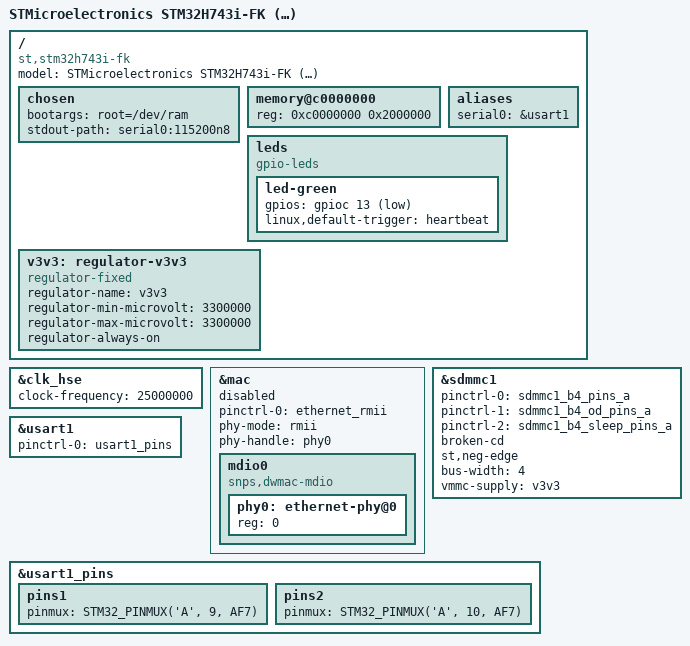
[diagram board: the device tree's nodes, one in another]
/dts-v1/;
#include "stm32h743.dtsi"
#include "stm32h7-pinctrl.dtsi"

/ {
	model = "STMicroelectronics STM32H743i-FK (反客科技)";
	compatible = "st,stm32h743i-fk", "st,stm32h743";

	chosen {
		bootargs = "root=/dev/ram";
		stdout-path = "serial0:115200n8";
	};

	memory@c0000000 {
		device_type = "memory";
		reg = <0xc0000000 0x2000000>;
	};

	aliases {
		serial0 = &usart1;
	};

	leds {
		compatible = "gpio-leds";
		led-green {
			gpios = <&gpioc 13 1>;
			linux,default-trigger = "heartbeat";
		};
    };

	v3v3: regulator-v3v3 {
		compatible = "regulator-fixed";
		regulator-name = "v3v3";
		regulator-min-microvolt = <3300000>;
		regulator-max-microvolt = <3300000>;
		regulator-always-on;
	};
};

&clk_hse {
	clock-frequency = <25000000>;
};

&mac {
	status = "disabled";
	pinctrl-0 = <&ethernet_rmii>;
	pinctrl-names = "default";
	phy-mode = "rmii";
	phy-handle = <&phy0>;

	mdio0 {
		#address-cells = <1>;
		#size-cells = <0>;
		compatible = "snps,dwmac-mdio";
		phy0: ethernet-phy@0 {
			reg = <0>;
		};
	};
};

&sdmmc1 {
	pinctrl-names = "default", "opendrain", "sleep";
	pinctrl-0 = <&sdmmc1_b4_pins_a>;
	pinctrl-1 = <&sdmmc1_b4_od_pins_a>;
	pinctrl-2 = <&sdmmc1_b4_sleep_pins_a>;
	broken-cd;
	st,neg-edge;
	bus-width = <4>;
	vmmc-supply = <&v3v3>;
	status = "okay";
};

&usart1 {
	pinctrl-0 = <&usart1_pins>;
	pinctrl-names = "default";
	status = "okay";
};

&usart1_pins {
	pins1 {
		pinmux = <STM32_PINMUX('A',  9, AF7)>;
	};
	pins2 {
		pinmux = <STM32_PINMUX('A', 10, AF7)>;
	};
};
